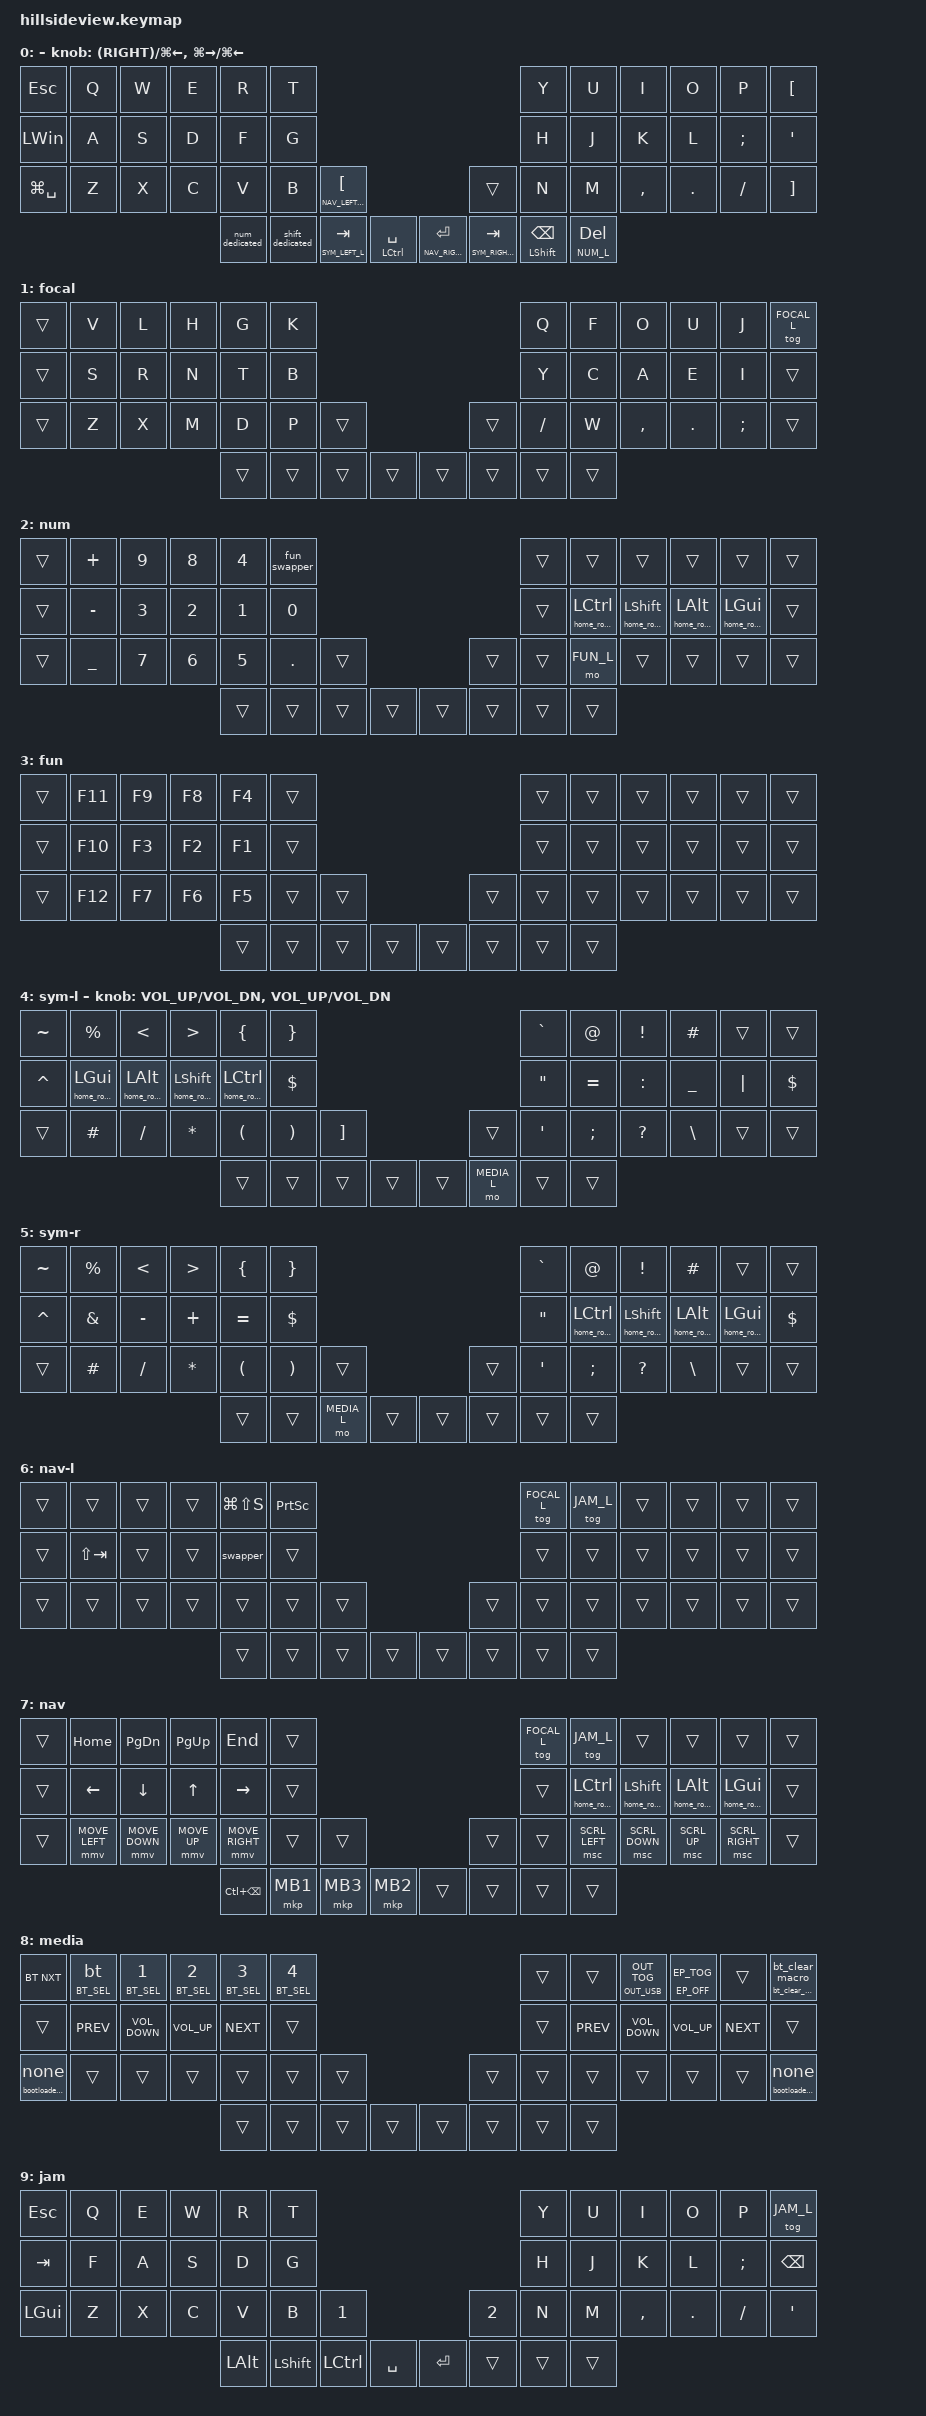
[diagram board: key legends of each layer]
/*
 * Copyright (c) 2022-2026 The ZMK Contributors
 *
 * SPDX-License-Identifier: MIT
 */

#include <dt-bindings/zmk/mouse.h>
#include <input/processors.dtsi>
#include <behaviors.dtsi>
#include <dt-bindings/zmk/bt.h>
#include <dt-bindings/zmk/ext_power.h>
#include <dt-bindings/zmk/keys.h>
#include <dt-bindings/zmk/outputs.h>
#include <dt-bindings/zmk/pointing.h>
#include <dt-bindings/zmk/input_transform.h>
#include <behaviors/num_word.dtsi>

#define QWERTY_L    0
#define FOCAL_L     1
#define NUM_L       2
#define FUN_L       3
#define SYM_LEFT_L  4
#define SYM_RIGHT_L 5
#define NAV_LEFT_L  6
#define NAV_RIGHT_L 7
#define MEDIA_L     8
#define JAM_L       9
#define Undo   LC(Z)
#define Cut    LC(X)
#define Copy   LC(C)
#define Paste  LC(V)
#define Redo   LC(Y)
#define DANGER_DELAY 3000
#define TAPPING_INTERVAL 250
#define QUICK_TAP_INTERVAL 200
#define PRIOR_IDLE_INTERVAL 40

/ {
    behaviors {
        home_row_sticky: home_row_sticky {
            compatible = "zmk,behavior-sticky-key";
            label = "HOME_ROW_STICKY";
            bindings = <&kp>;
            #binding-cells = <1>;
            release-after-ms = <1000>;
            quick-release;
            ignore-modifiers;
        };

        shift_dedicated: shift_dedicated {
            compatible = "zmk,behavior-tap-dance";
            label = "SHIFT_DEDICATED";
            #binding-cells = <0>;
            bindings = <&sticky_shift LSHIFT>, <&caps_word>;
        };

        sticky_shift: sticky_shift {
            compatible = "zmk,behavior-sticky-key";
            label = "STICKY_SHIFT";
            bindings = <&sk>;
            #binding-cells = <1>;
            release-after-ms = <600>;
            quick-release;
            ignore-modifiers;
        };

        num_dedicated: num_dedicated {
            compatible = "zmk,behavior-tap-dance";
            label = "NUM_DEDICATED";
            #binding-cells = <0>;
            bindings = <&num_word NUM_L>, <&mo NUM_L>;
        };

        thumb_key_layer: thumb_key_layer {
            compatible = "zmk,behavior-hold-tap";
            label = "THUMB_KEY_LAYER";
            bindings = <&mo>, <&kp>;

            #binding-cells = <2>;
            tapping-term-ms = <TAPPING_INTERVAL>;
            quick-tap-ms = <QUICK_TAP_INTERVAL>;
            require-prior-idle-ms = <PRIOR_IDLE_INTERVAL>;
            hold-while-undecided;
        };

        thumb_key_mod: thumb_key_mod {
            compatible = "zmk,behavior-hold-tap";
            label = "THUMB_KEY_MOD";
            bindings = <&kp>, <&kp>;

            #binding-cells = <2>;
            tapping-term-ms = <TAPPING_INTERVAL>;
            quick-tap-ms = <QUICK_TAP_INTERVAL>;
            require-prior-idle-ms = <0>;
            hold-while-undecided;
        };

        thumb_active_key_mod: thumb_active_key_mod {
            compatible = "zmk,behavior-hold-tap";
            label = "THUMB_ACTIVE_KEY_MOD";
            bindings = <&kp>, <&kp>;

            #binding-cells = <2>;
            tapping-term-ms = <TAPPING_INTERVAL>;
            quick-tap-ms = <QUICK_TAP_INTERVAL>;
            require-prior-idle-ms = <PRIOR_IDLE_INTERVAL>;
            hold-while-undecided;
        };

        thumb_active_key_layer: thumb_active_key_layer {
            compatible = "zmk,behavior-hold-tap";
            label = "THUMB_ACTIVE_KEY_LAYER";
            bindings = <&mo>, <&kp>;

            #binding-cells = <2>;
            tapping-term-ms = <TAPPING_INTERVAL>;
            quick-tap-ms = <QUICK_TAP_INTERVAL>;
            require-prior-idle-ms = <PRIOR_IDLE_INTERVAL>;
            hold-while-undecided;
        };

        swapper: swapper {
            compatible = "zmk,behavior-smart-toggle";
            #binding-cells = <0>;
            bindings = <&kp LALT>, <&kp TAB>;

            ignored-key-positions = <13>;
            // shift for both left and right symbol layers
        };

        fun_swapper: fun_swapper {
            compatible = "zmk,behavior-smart-toggle";
            #binding-cells = <0>;
            bindings = <&mo FUN_L>, <&none>;

            ignored-key-positions =
                <1>,
                <2>,
                <3>,
                <4>,
                <13>,
                <14>,
                <15>,
                <16>,
                <25>,
                <26>,
                <27>,
                <28>;

            // F-keys
        };

        bt_or_reset_hold: bt_or_reset_hold {
            compatible = "zmk,behavior-hold-tap";
            label = "BT_OR_RESET_HOLD";
            bindings = <&bt_clear_macro>, <&bt>;

            #binding-cells = <2>;
            tapping-term-ms = <DANGER_DELAY>;
            flavor = "tap-preferred";
        };

        bt_reset_hold: bt_reset_hold {
            compatible = "zmk,behavior-hold-tap";
            label = "BT_RESET_HOLD";
            bindings = <&bt_clear_all_macro>, <&bt_clear_macro>;

            #binding-cells = <2>;
            tapping-term-ms = <DANGER_DELAY>;
            flavor = "tap-preferred";
        };

        bootloader_reset_hold: bootloader_reset_hold {
            compatible = "zmk,behavior-hold-tap";
            label = "BOOTLOADER_RESET_HOLD";
            bindings = <&bootloader_reset_macro>, <&none>;

            #binding-cells = <2>;
            tapping-term-ms = <DANGER_DELAY>;
            flavor = "tap-preferred";
        };

        output_hold: output_hold {
            compatible = "zmk,behavior-hold-tap";
            label = "OUTPUT_HOLD";
            bindings = <&out>, <&out>;

            #binding-cells = <2>;
            flavor = "tap-preferred";
            tapping-term-ms = <DANGER_DELAY>;
        };

        ext_power_hold: ext_power_hold {
            compatible = "zmk,behavior-hold-tap";
            label = "EXT_POWER_HOLD";
            bindings = <&ext_power>, <&ext_power>;

            #binding-cells = <2>;
            tapping-term-ms = <DANGER_DELAY>;
            flavor = "tap-preferred";
        };

        kp_encoder: kp_encoder {
            compatible = "zmk,behavior-sensor-rotate-var";
            #sensor-binding-cells = <2>;
            bindings = <&kp>, <&kp>;
        };
    };

    macros {
        bt_clear_macro: bt_clear_macro {
            compatible = "zmk,behavior-macro";
            #binding-cells = <0>;
            bindings = <&bt BT_CLR>;
            label = "BT_CLEAR_MACRO";
        };

        bt_clear_all_macro: bt_clear_all_macro {
            compatible = "zmk,behavior-macro";
            #binding-cells = <0>;
            bindings = <&bt BT_CLR_ALL>;
            label = "BT_CLEAR_ALL_MACRO";
        };

        sys_reset_macro: sys_reset_macro {
            compatible = "zmk,behavior-macro";
            #binding-cells = <0>;
            bindings = <&sys_reset>;
            label = "SYS_RESET_MACRO";
        };

        bootloader_reset_macro: bootloader_reset_macro {
            compatible = "zmk,behavior-macro";
            #binding-cells = <0>;
            bindings = <&bootloader>;
            label = "BOOTLOADER_RESET_MACRO";
        };
    };

    scroll_mapper: scroll_mapper {
        compatible = "zmk,input-processor-code-mapper";
        #input-processor-cells = <0>;
        type = <INPUT_EV_REL>;
        map = <INPUT_REL_X INPUT_REL_HWHEEL>,
              <INPUT_REL_Y INPUT_REL_WHEEL>;
    };

    scroll_scaler: scroll_scaler {
        compatible = "zmk,input-processor-scaler";
        #input-processor-cells = <2>;
        type = <INPUT_EV_REL>;
        codes = <INPUT_REL_WHEEL INPUT_REL_HWHEEL>;
        /* Accumulate fractional deltas instead of truncating to zero — without this, slow finger movements produce no scroll at all */
        track-remainders;
    };

    input_processors {
        touch_processor: touch_processor {
            compatible = "zmk,input-processor-behaviors";
            #input-processor-cells = <0>;

            codes = <INPUT_BTN_TOUCH>;      // watch for the 'touch' pseudo button
            // bindings  = <&mo NAV_RIGHT_L>;            // Activate Layer 4 while held &mo 4
            bindings  = <&mkp MB1>; // emulate mouse click
        };

        /omit-if-no-ref/ zip_temp_layer: zip_temp_layer {
            compatible = "zmk,input-processor-temp-layer";
            #input-processor-cells = <2>;
            require-prior-idle-ms = <2000>;
            excluded-positions = <0>;
        };
    };

    tpad_peripheral_listener {
            status = "okay";
            input-processors = <&zip_xy_scaler 3 2>, <&zip_temp_layer NAV_RIGHT_L 100>;

            base {
                layers = <QWERTY_L>;
                process-next;
                input-processors = <&touch_processor>;
            };

            precise {
                    layers = <NAV_LEFT_L>;
                    input-processors = <&zip_xy_scaler 1 2>;
            };
            scroll {
                    layers = <SYM_RIGHT_L SYM_LEFT_L>;
                    input-processors = <&scroll_mapper &scroll_scaler 1 20>,
                                       <&zip_xy_to_scroll_mapper>,
                                       <&zip_scroll_transform (INPUT_TRANSFORM_X_INVERT)>;
            };
    };

    keymap {
        compatible = "zmk,keymap";

        default_layer {
            label = "";
            /* QWERTY
 * -------------------------------------------------------------------------------------------------------------------------------------
 * | ESC   |   Q   |   W   |   E   |   R   |   T   |-----------------------------------|   Y   |   U   |   I   |   O   |   P   |   [   |
 * | WIN   |   A   |   S   |   D   |   F   |   G   |-----------------------------------|   H   |   J   |   K   |   L   |   ;   |   '   |
 * | NUML  |   Z   |   X   |   C   |   V   |   B   |  [    |-------------------|       |   N   |   M   |   ,   |   .   |   /   |   ]   |
 *                                 |  NUML |  SHFT |  TAB  |  SPC  |---|  ENTR | BCKSP |  SHFT |  DEL  |
 */

            bindings = <
&kp ESCAPE       &kp Q  &kp W  &kp E  &kp R                             &kp T                                                                                                                                                                         &kp Y                            &kp U                          &kp I      &kp O    &kp P      &kp LEFT_BRACKET
&kp LEFT_WIN     &kp A  &kp S  &kp D  &kp F                             &kp G                                                                                                                                                                         &kp H                            &kp J                          &kp K      &kp L    &kp SEMI   &kp SQT
&kp LG(SPACE)    &kp Z  &kp X  &kp C  &kp V                             &kp B             &thumb_key_layer NAV_LEFT_L LEFT_BRACKET                                                                                  &trans                            &kp N                            &kp M                          &kp COMMA  &kp DOT  &kp SLASH  &kp RIGHT_BRACKET
                                      &num_dedicated                    &shift_dedicated  &thumb_key_layer SYM_LEFT_L TAB           &thumb_active_key_mod LCTRL SPACE    &thumb_active_key_layer NAV_RIGHT_L ENTER  &thumb_key_layer SYM_RIGHT_L TAB  &thumb_key_mod LSHIFT BACKSPACE  &thumb_key_layer NUM_L DELETE
            >;

            // sensor-bindings = <&inc_dec_kp C_VOL_UP C_VOL_DN &inc_dec_kp PG_UP PG_DN>;
            // sensor-bindings = <&kp_encoder LG(LEFT) LG(RIGHT) &kp_encoder LG(LEFT) LG(RIGHT)>;
            // sensor-bindings = <&kp_encoder RIGHT LEFT &kp_encoder RIGHT LEFT>;
            sensor-bindings = <&kp_encoder (RIGHT) LG(LEFT) &kp_encoder LG(RIGHT) LG(LEFT)>;
        };

        focal_layer {
            label = "focal";
            bindings = <
&trans  &kp V  &kp L  &kp H  &kp G   &kp K                                     &kp Q     &kp F   &kp O      &kp U    &kp J     &tog FOCAL_L
&trans  &kp S  &kp R  &kp N  &kp T   &kp B                                     &kp Y     &kp C   &kp A      &kp E    &kp I     &trans
&trans  &kp Z  &kp X  &kp M  &kp D   &kp P   &trans                    &trans  &kp FSLH  &kp W   &kp COMMA  &kp DOT  &kp SEMI  &trans
                             &trans  &trans  &trans  &trans    &trans  &trans  &trans    &trans
            >;
        };

        num_layer {
            label = "num";
            bindings = <
&trans  &kp PLUS        &kp N9  &kp N8  &kp N4  &fun_swapper                                    &trans  &trans                  &trans                  &trans                 &trans                 &trans
&trans  &kp MINUS       &kp N3  &kp N2  &kp N1  &kp N0                                          &trans  &home_row_sticky LCTRL  &home_row_sticky LSHFT  &home_row_sticky LALT  &home_row_sticky LGUI  &trans
&trans  &kp UNDERSCORE  &kp N7  &kp N6  &kp N5  &kp DOT       &trans                    &trans  &trans  &mo FUN_L               &trans                  &trans                 &trans                 &trans
                                        &trans  &trans        &trans  &trans    &trans  &trans  &trans  &trans
            >;
        };

        fun_layer {
            label = "fun";
            bindings = <
&trans  &kp F11  &kp F9  &kp F8  &kp F4  &trans                                    &trans  &trans  &trans  &trans  &trans  &trans
&trans  &kp F10  &kp F3  &kp F2  &kp F1  &trans                                    &trans  &trans  &trans  &trans  &trans  &trans
&trans  &kp F12  &kp F7  &kp F6  &kp F5  &trans  &trans                    &trans  &trans  &trans  &trans  &trans  &trans  &trans
                                 &trans  &trans  &trans  &trans    &trans  &trans  &trans  &trans
            >;
        };

            /* SYM_LEFT_L
 * -------------------------------------------------------------------------------------------------------------------------------------
 * |   ~   |   %   |   <   |   >   |   {   |   }   |-----------------------------------|   `   |   @   |   !   |   #   |       |       |
 * |   ^   |  WIN  | LALT  | LSHFT | LCTRL |   $   |-----------------------------------|   "   |   =   |   :   |   _   |   |   |   $   |
 * |       |   #   |   /   |   *   |   (   |   )   |  ]    |-------------------|       |   '   |   ;   |   ?   |   \   |   /   |       |
 *                                 |  NUML |  SHFT |  TAB  |  SPC  |---|  ENTR | BCKSP |  SHFT |  DEL  |
 */
        sym_left_layer {
            label = "sym-l";
            bindings = <
&kp TILDE  &kp PERCENT            &kp LT                 &kp GT                  &kp LEFT_BRACE          &kp RIGHT_BRACE                                                          &kp GRAVE          &kp AT         &kp EXCLAMATION  &kp HASH        &trans    &trans
&kp CARET  &home_row_sticky LGUI  &home_row_sticky LALT  &home_row_sticky LSHFT  &home_row_sticky LCTRL  &kp DOLLAR                                                               &kp DOUBLE_QUOTES  &kp EQUAL      &kp COLON        &kp UNDERSCORE  &kp PIPE  &kp DOLLAR
&trans     &kp HASH               &kp SLASH              &kp STAR                &kp LEFT_PARENTHESIS    &kp RIGHT_PARENTHESIS  &kp RIGHT_BRACKET                    &trans       &kp SQT            &kp SEMICOLON  &kp QUESTION     &kp BACKSLASH   &trans    &trans
                                                                                 &trans                  &trans                 &trans             &trans    &trans  &mo MEDIA_L  &trans             &trans
            >;
            sensor-bindings = <&inc_dec_kp C_VOL_UP C_VOL_DN &inc_dec_kp C_VOL_UP C_VOL_DN>;
        };

        sym_right_layer {
            label = "sym-r";
            bindings = <
&kp TILDE  &kp PERCENT    &kp LT     &kp GT    &kp LEFT_BRACE        &kp RIGHT_BRACE                                               &kp GRAVE          &kp AT_SIGN             &kp EXCLAMATION          &kp HASH               &trans                 &trans
&kp CARET  &kp AMPERSAND  &kp MINUS  &kp PLUS  &kp EQUAL             &kp DOLLAR                                                    &kp DOUBLE_QUOTES  &home_row_sticky LCTRL  &home_row_sticky LSHIFT  &home_row_sticky LALT  &home_row_sticky LGUI  &kp DOLLAR
&trans     &kp HASH       &kp SLASH  &kp STAR  &kp LEFT_PARENTHESIS  &kp RIGHT_PARENTHESIS  &trans                         &trans  &kp SQT            &kp SEMICOLON           &kp QUESTION             &kp BACKSLASH          &trans                 &trans
                                               &trans                &trans                 &mo MEDIA_L  &trans    &trans  &trans  &trans             &trans
            >;
        };

        nav_left_layer {
            label = "nav-l";
            bindings = <
&trans  &trans       &trans  &trans  &kp LG(LS(S))  &kp PRINTSCREEN                                    &tog FOCAL_L  &tog JAM_L  &trans  &trans  &trans  &trans
&trans  &kp LS(TAB)  &trans  &trans  &swapper       &trans                                             &trans        &trans      &trans  &trans  &trans  &trans
&trans  &trans       &trans  &trans  &trans         &trans           &trans                    &trans  &trans        &trans      &trans  &trans  &trans  &trans
                                     &trans         &trans           &trans  &trans    &trans  &trans  &trans        &trans
            >;
        };

        nav_right_layer {
            label = "nav";
            bindings = <
&trans  &kp HOME        &kp PAGE_DOWN   &kp PAGE_UP   &kp END            &trans                                          &tog FOCAL_L  &tog JAM_L              &trans                   &trans                     &trans                 &trans
&trans  &kp LEFT        &kp DOWN        &kp UP        &kp RIGHT          &trans                                          &trans        &home_row_sticky LCTRL  &home_row_sticky LSHIFT  &home_row_sticky LEFT_ALT  &home_row_sticky LGUI  &trans
&trans  &mmv MOVE_LEFT  &mmv MOVE_DOWN  &mmv MOVE_UP  &mmv MOVE_RIGHT    &trans    &trans                        &trans  &trans        &msc SCRL_LEFT          &msc SCRL_DOWN           &msc SCRL_UP               &msc SCRL_RIGHT        &trans
                                                      &kp LC(BACKSPACE)  &mkp MB1  &mkp MB3  &mkp MB2    &trans  &trans  &trans        &trans
            >;
        };

        media_layer {
            label = "media";
            bindings = <
&bt BT_NXT                  &bt_or_reset_hold BT_SEL 0  &bt_or_reset_hold BT_SEL 1  &bt_or_reset_hold BT_SEL 2  &bt_or_reset_hold BT_SEL 3  &bt_or_reset_hold BT_SEL 4                                    &trans  &trans      &output_hold OUT_USB OUT_TOG  &ext_power_hold EP_OFF EP_TOG  &trans      &bt_reset_hold 0 0
&trans                      &kp C_PREV                  &kp C_VOLUME_DOWN           &kp C_VOLUME_UP             &kp C_NEXT                  &trans                                                        &trans  &kp C_PREV  &kp C_VOLUME_DOWN             &kp C_VOLUME_UP                &kp C_NEXT  &trans
&bootloader_reset_hold 0 0  &trans                      &trans                      &trans                      &trans                      &trans                      &trans                    &trans  &trans  &trans      &trans                        &trans                         &trans      &bootloader_reset_hold 0 0
                                                                                                                &trans                      &trans                      &trans  &trans    &trans  &trans  &trans  &trans
            >;
        };

        jam_layer {
            label = "jam";
            bindings = <
&kp ESC   &kp Q  &kp E  &kp W  &kp R     &kp T                                                 &kp Y   &kp U   &kp I      &kp O    &kp P     &tog JAM_L
&kp TAB   &kp F  &kp A  &kp S  &kp D     &kp G                                                 &kp H   &kp J   &kp K      &kp L    &kp SEMI  &kp BSPC
&kp LGUI  &kp Z  &kp X  &kp C  &kp V     &kp B      &kp N1                             &kp N2  &kp N   &kp M   &kp COMMA  &kp DOT  &kp FSLH  &kp APOS
                               &kp LALT  &kp LSHFT  &kp LCTRL  &kp SPACE    &kp ENTER  &trans  &trans  &trans
            >;
        };
    };
};
